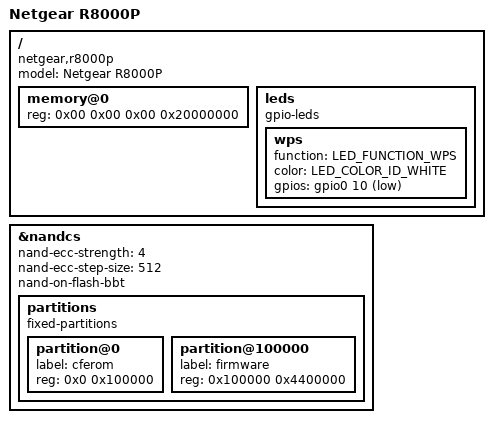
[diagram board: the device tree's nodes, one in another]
// SPDX-License-Identifier: GPL-2.0-or-later OR MIT

#include <dt-bindings/gpio/gpio.h>
#include <dt-bindings/input/input.h>
#include <dt-bindings/leds/common.h>

#include "bcm4906.dtsi"

/ {
	compatible = "netgear,r8000p", "brcm,bcm4906", "brcm,bcm4908";
	model = "Netgear R8000P";

	memory@0 {
		device_type = "memory";
		reg = <0x00 0x00 0x00 0x20000000>;
	};

	leds {
		compatible = "gpio-leds";

		wps {
			function = LED_FUNCTION_WPS;
			color = <LED_COLOR_ID_WHITE>;
			gpios = <&gpio0 10 GPIO_ACTIVE_LOW>;
		};
	};
};

&nandcs {
	nand-ecc-strength = <4>;
	nand-ecc-step-size = <512>;
	nand-on-flash-bbt;

	#address-cells = <1>;
	#size-cells = <0>;

	partitions {
		compatible = "fixed-partitions";
		#address-cells = <1>;
		#size-cells = <1>;

		partition@0 {
			label = "cferom";
			reg = <0x0 0x100000>;
		};

		partition@100000 {
			label = "firmware";
			reg = <0x100000 0x4400000>;
		};
	};
};
